AUTOSAR XML (schema 00048)
# Original work, MIT licence. No proprietary content.
standard types defined: float32, uint8, boolean
package /DataTypes/ImplTypes
  4 x impl type, all with category=VALUE:
    Volt_T: base-type=float32
    Float_T: base-type=float32
    Uint8_T: base-type=uint8
    Boolean_T: base-type=boolean
package /PortInterfaces
  4 x sender receiver interface:
    IF_Volt
      data v: type=Volt_T
    IF_Float
      data val: type=Float_T
    IF_U8
      data val: type=Uint8_T
    IF_Bool
      data flag: type=Boolean_T
package /SwComponentTypes
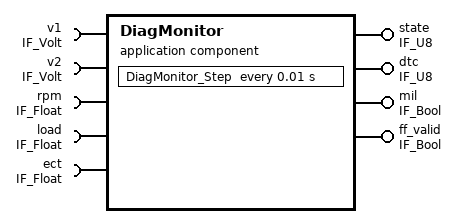
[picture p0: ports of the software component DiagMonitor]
  application sw component type DiagMonitor
    5 x require port:
      v1: required-interface=IF_Volt
      v2: required-interface=IF_Volt
      rpm: required-interface=IF_Float
      load: required-interface=IF_Float
      ect: required-interface=IF_Float
    4 x provide port:
      state: provided-interface=IF_U8
      dtc: provided-interface=IF_U8
      mil: provided-interface=IF_Bool
      ff_valid: provided-interface=IF_Bool
    behavior DiagMonitor_IB
      timing event EV_10ms: start-on-event=DiagMonitor_Step, period=0.01
      runnable DiagMonitor_Step
